# MINI51XAE_v1 register map
File version: 1.0
Registers are 32-bit, read-write, reset 0x0 unless marked. A register's access mark holds for its fields unless they carry their own. Offsets are from the block's base; [hi:lo] are bit positions; {n}, {i} and the like mark numbered series; 'fields as' and 'values as' point back to an identical list.

## GP — GPIO Register Map
Base 0x50004000
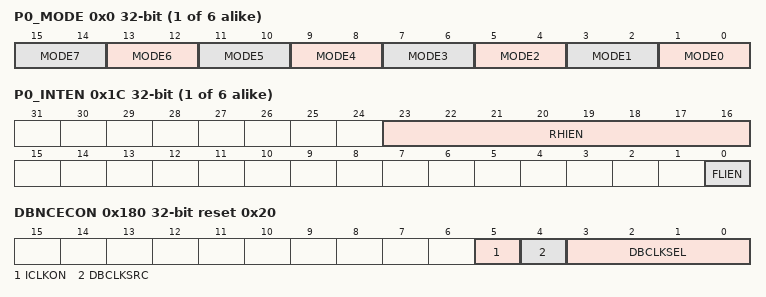
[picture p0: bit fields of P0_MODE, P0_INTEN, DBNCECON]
{0x0+0x40*i} P{i}_MODE (reset mask 0xFFFF0000) (i=0..5) — P{i} I/O Mode Control
  [2n+1:2n] MODE{n} (n=0..7) — Port 0-5 I/O Pin [N] Mode Control
{0x4+0x40*i} P{i}_DINOFF (i=0..5) — P{i} Digital Input Path Disable Control
  [23:16] DINOFF — Port 0-5 Pin [N] Digital Input Path Disable Control
    0=Px.n digital input path Enabled; 1=Px.n digital input path Disabled (digital input tied to low)
{0x8+0x40*i} P{i}_DOUT reset 0xF7 (i=0..5) — P{i} Data Output Value
  [7:0] DOUT — Port 0-5 Pin [N] Output Value. Each of these bits controls the status of a Px.n pin when the Px.n is configured as Push-pull output, Open-drain output and Quasi-bidirectional mode.
    0=Px.n will drive Low if the Px.n pin is configured as Push-pull output, Open-drain output or Quasi-bidirectional mode; 1=Px.n will drive High if the Px.n pin is configured as Push-pull output or Quasi-bidirectional mode
{0xC+0x40*i} P{i}_DATMSK (i=0..5) — P{i} Data Output Write Mask
  [7:0] DATMSK — Port 0-5 Pin [N] Data Output Write Mask. These bits are used to protect the corresponding Px_DOUT[n] bit. When the DATMSK[n] bit is set to 1, the corresponding Px_DOUT[n] bit is protected. If the write signal is masked, writing data to the protect bit is ignored. Note2: This function only protects the corresponding Px_DOUT[n] bit, and will not protect the corresponding Pxn_PDIO bit.
    0=Corresponding Px_DOUT[n] bit can be updated; 1=Corresponding Px_DOUT[n] bit is protected
{0x10+0x40*i} P{i}_PIN ro (reset mask 0xFFFFFF00) (i=0..5) — P{i} Pin Value
  [7:0] PIN — Port 0-5 Pin [N] Pin Value. Each bit of the register reflects the actual status of the respective Px.n pin. If the bit is 1, it indicates the corresponding pin status is high; else the pin status is low.
{0x14+0x40*i} P{i}_DBEN (i=0..5) — P{i} De-bounce Enable Control
  [7:0] DBEN — Port 0-5 Pin [N] Input Signal De-Bounce Enable Control. DBEN[n] bit is used to enable the de-bounce function for each corresponding bit. If the input signal pulse width cannot be sampled by continuous two de-bounce sample cycle, the input signal transition is seen as the signal bounce and will not trigger the interrupt. The de-bounce clock source is controlled by DBNCECON[4], one de-bounce sample cycle period is controlled by DBNCECON[3:0]. Note2: If Px.n pin is chosen as Power-down wake-up source, user should be disable the de-bounce function before entering Power-down mode to avoid the second interrupt event occurred after system waken up which caused by Px.n de-bounce function.
    0=Px.n de-bounce function Disabled; 1=Px.n de-bounce function Enabled
{0x18+0x40*i} P{i}_INTTYPE (i=0..5) — P{i} Interrupt Mode Control
  [7:0] INTTYPE — Port 0-5 Pin [N] Edge Or Level Detection Interrupt Mode Control. INTTYPE[n] bit is used to control the triggered interrupt is by level trigger or by edge trigger. If the interrupt is by edge trigger, the trigger source can be controlled by de-bounce. If the interrupt is by level trigger, the input source is sampled by one HCLK clock and generates the interrupt.
    0=Edge trigger interrupt; 1=Level trigger interrupt
{0x1C+0x40*i} P{i}_INTEN (i=0..5) — P{i} Interrupt Enable Control
  [23:16] RHIEN — Port 0-5 Pin [N] Interrupt Enable By Input Rising Edge Or Input Level High. RHIEN[n] bit is used to enable the interrupt for each of the corresponding input Px.n pin. Set bit to 1 also enable the pin wake-up function. When setting the RHIEN[n] bit to 1: If the interrupt is level trigger (INTTYPE[n] is 1), the input Px.n pin will generate the interrupt while this pin state is at high level. If the interrupt is edge trigger (INTTYPE[n] is 0), the input Px.n pin will generate the interrupt while this pin state changed from low to high.
    0=Px.n level high or low to high interrupt Disabled; 1=Px.n level high or low to high interrupt Enabled
  [0] FLIEN — Port 0-5 Pin [N] Interrupt Enable By Input Falling Edge Or Input Level Low. FLIEN[n] is used to enable the interrupt for each of the corresponding input Px.n pin. Set bit to 1 also enable the pin wake-up function. When setting the FLIEN[n] bit to 1: If the interrupt is level trigger (INTTYPE[n] is 1), the input Px.n pin will generate the interrupt while this pin state is at low level. If the interrupt is edge mode trigger (INTTYPE[n] is 0), the input Px.n pin will generate the interrupt while this pin state changed from high to low.
    0=Px.n low level or high to low interrupt Disabled; 1=Px.n low level or high to low interrupt Enabled
{0x20+0x40*i} P{i}_INTSRC (i=0..5) — P{i} Interrupt Source Flag
  [7:0] INTSRC — Port 0-5 Pin [N] Interrupt Source Flag. Write :
    0=No action. No interrupt at Px.n; 1=Clear the corresponding pending interrupt. Px.n generates an interrupt
0x180 DBNCECON reset 0x20 — Interrupt De-bounce Control
  [5] ICLKON — Interrupt Clock On Mode. Note: It is recommended to turn off this bit to save system power if no special application concern.
    0=Edge detection circuit is active only if I/O pin corresponding Px_INTEN bit is set to 1; 1=All I/O pins edge detection circuit is always active after reset
  [4] DBCLKSRC — De-Bounce Counter Clock Source Selection
    0=De-bounce counter clock source is the HCLK; 1=De-bounce counter clock source is the 10 kHz internal low speed oscillator
  [3:0] DBCLKSEL — De-Bounce Sampling Cycle Selection
    0=Sample interrupt input once per 1 clock; 1=Sample interrupt input once per 2 clocks; 2=Sample interrupt input once per 4 clocks; 3=Sample interrupt input once per 8 clocks; 4=Sample interrupt input once per 16 clocks; 5=Sample interrupt input once per 32 clocks; 6=Sample interrupt input once per 64 clocks; 7=Sample interrupt input once per 128 clocks; 8=Sample interrupt input once per 256 clocks; 9=Sample interrupt input once per 512 clocks; 10=Sample interrupt input once per 1024 clocks; 11=Sample interrupt input once per 2048 clocks; 12=Sample interrupt input once per 4096 clocks; 13=Sample interrupt input once per 8192 clocks; 14=Sample interrupt input once per 16384 clocks; 15=Sample interrupt input once per 32768 clocks
0x200 P00_PDIO reset 0x1 — GPIO P0.0 Pin Data Input/Output
  [0] PDIO — GPIO Px.n Pin Data Input/Output. Writing this bit can control one GPIO pin output value. For example, writing P01_PDIO will reflect the written value to bit P0_DOUT[1], reading P01_PDIO will return the value of P0_PIN[1]. Note: The writing operation will not be affected by register Px_DATMSK[n].
    0=Corresponding GPIO pin set to low. Corresponding GPIO pin status is low; 1=Corresponding GPIO pin set to high. Corresponding GPIO pin status is high
0x204 P01_PDIO reset 0x1 — GPIO P0.1 Pin Data Input/Output
  fields as P00_PDIO
0x210 P04_PDIO reset 0x1 — GPIO P0.4 Pin Data Input/Output
  fields as P00_PDIO
0x214 P05_PDIO reset 0x1 — GPIO P0.5 Pin Data Input/Output
  fields as P00_PDIO
0x218 P06_PDIO reset 0x1 — GPIO P0.6 Pin Data Input/Output
  fields as P00_PDIO
0x21C P07_PDIO reset 0x1 — GPIO P0.7 Pin Data Input/Output
  fields as P00_PDIO
0x220 P10_PDIO reset 0x1 — GPIO P1.0 Pin Data Input/Output
  fields as P00_PDIO
0x228 P12_PDIO reset 0x1 — GPIO P1.2 Pin Data Input/Output
  fields as P00_PDIO
0x22C P13_PDIO reset 0x1 — GPIO P1.3 Pin Data Input/Output
  fields as P00_PDIO
0x230 P14_PDIO reset 0x1 — GPIO P1.4 Pin Data Input/Output
  fields as P00_PDIO
0x234 P15_PDIO reset 0x1 — GPIO P1.5 Pin Data Input/Output
  fields as P00_PDIO
0x238 P16_PDIO reset 0x1 — GPIO P1.6 Pin Data Input/Output
  fields as P00_PDIO
0x248 P22_PDIO reset 0x1 — GPIO P2.2 Pin Data Input/Output
  fields as P00_PDIO
0x24C P23_PDIO reset 0x1 — GPIO P2.3 Pin Data Input/Output
  fields as P00_PDIO
0x250 P24_PDIO reset 0x1 — GPIO P2.4 Pin Data Input/Output
  fields as P00_PDIO
0x254 P25_PDIO reset 0x1 — GPIO P2.5 Pin Data Input/Output
  fields as P00_PDIO
0x258 P26_PDIO reset 0x1 — GPIO P2.6 Pin Data Input/Output
  fields as P00_PDIO
0x25C P27_PDIO reset 0x1 — GPIO P2.7 Pin Data Input/Output
  fields as P00_PDIO
0x260 P30_PDIO reset 0x1 — GPIO P3.0 Pin Data Input/Output
  fields as P00_PDIO
0x264 P31_PDIO reset 0x1 — GPIO P3.1 Pin Data Input/Output
  fields as P00_PDIO
0x268 P32_PDIO reset 0x1 — GPIO P3.2 Pin Data Input/Output
  fields as P00_PDIO
0x270 P34_PDIO reset 0x1 — GPIO P3.4 Pin Data Input/Output
  fields as P00_PDIO
0x274 P35_PDIO reset 0x1 — GPIO P3.5 Pin Data Input/Output
  fields as P00_PDIO
0x278 P36_PDIO reset 0x1 — GPIO P3.6 Pin Data Input/Output
  fields as P00_PDIO
0x27C P37_PDIO reset 0x1 — GPIO P3.7 Pin Data Input/Output
  fields as P00_PDIO
0x298 P46_PDIO reset 0x1 — GPIO P4.6 Pin Data Input/Output
  fields as P00_PDIO
0x29C P47_PDIO reset 0x1 — GPIO P4.7 Pin Data Input/Output
  fields as P00_PDIO
0x2A0 P50_PDIO reset 0x1 — GPIO P5.0 Pin Data Input/Output
  fields as P00_PDIO
0x2A4 P51_PDIO reset 0x1 — GPIO P5.1 Pin Data Input/Output
  fields as P00_PDIO
0x2A8 P52_PDIO reset 0x1 — GPIO P5.2 Pin Data Input/Output
  fields as P00_PDIO
0x2AC P53_PDIO reset 0x1 — GPIO P5.3 Pin Data Input/Output
  fields as P00_PDIO
0x2B0 P54_PDIO reset 0x1 — GPIO P5.4 Pin Data Input/Output
  fields as P00_PDIO
0x2B4 P55_PDIO reset 0x1 — GPIO P5.5 Pin Data Input/Output
  fields as P00_PDIO
